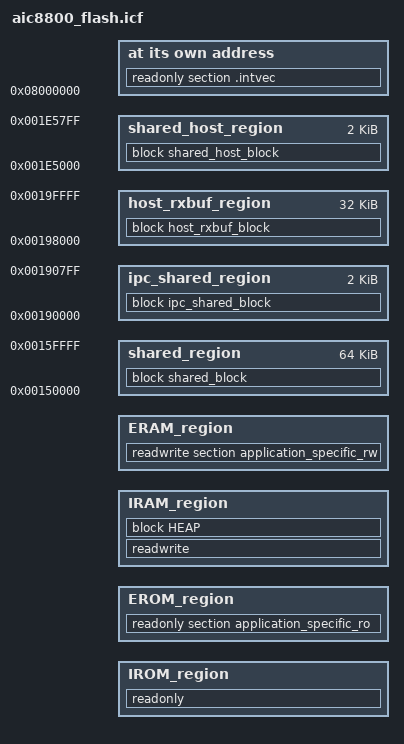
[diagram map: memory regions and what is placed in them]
/*###ICF### Section handled by ICF editor, don't touch! ****/
/*-Editor annotation file-*/
/* IcfEditorFile="$TOOLKIT_DIR$\config\ide\IcfEditor\cortex_v1_4.xml" */
/*-Specials-*/
define symbol __ICFEDIT_intvec_start__ = 0x08000000;
/*-Memory Regions-*/
define symbol __ICFEDIT_region_IROM1_start__ = 0x08000000;
define symbol __ICFEDIT_region_IROM1_end__   = 0x081FBFFF;
define symbol __ICFEDIT_region_IROM2_start__ = 0x0;
define symbol __ICFEDIT_region_IROM2_end__   = 0x0;
define symbol __ICFEDIT_region_EROM1_start__ = 0x0;
define symbol __ICFEDIT_region_EROM1_end__   = 0x0;
define symbol __ICFEDIT_region_EROM2_start__ = 0x0;
define symbol __ICFEDIT_region_EROM2_end__   = 0x0;
define symbol __ICFEDIT_region_EROM3_start__ = 0x0;
define symbol __ICFEDIT_region_EROM3_end__   = 0x0;
define symbol __ICFEDIT_region_IRAM1_start__ = 0x001A0000;
define symbol __ICFEDIT_region_IRAM1_end__   = 0x001C7FFF;
define symbol __ICFEDIT_region_IRAM2_start__ = 0x0;
define symbol __ICFEDIT_region_IRAM2_end__   = 0x0;
define symbol __ICFEDIT_region_ERAM1_start__ = 0x0;
define symbol __ICFEDIT_region_ERAM1_end__   = 0x0;
define symbol __ICFEDIT_region_ERAM2_start__ = 0x0;
define symbol __ICFEDIT_region_ERAM2_end__   = 0x0;
define symbol __ICFEDIT_region_ERAM3_start__ = 0x0;
define symbol __ICFEDIT_region_ERAM3_end__   = 0x0;
/*-Sizes-*/
define symbol __ICFEDIT_size_cstack__     = 0x1000;
define symbol __ICFEDIT_size_proc_stack__ = 0x0;
define symbol __ICFEDIT_size_heap__       = 0x0;
/**** End of ICF editor section. ###ICF###*/

define memory mem with size = 4G;
define symbol use_IROM1 = (__ICFEDIT_region_IROM1_start__ != 0x0 || __ICFEDIT_region_IROM1_end__ != 0x0);
define symbol use_IROM2 = (__ICFEDIT_region_IROM2_start__ != 0x0 || __ICFEDIT_region_IROM2_end__ != 0x0);
define symbol use_EROM1 = (__ICFEDIT_region_EROM1_start__ != 0x0 || __ICFEDIT_region_EROM1_end__ != 0x0);
define symbol use_EROM2 = (__ICFEDIT_region_EROM2_start__ != 0x0 || __ICFEDIT_region_EROM2_end__ != 0x0);
define symbol use_EROM3 = (__ICFEDIT_region_EROM3_start__ != 0x0 || __ICFEDIT_region_EROM3_end__ != 0x0);
define symbol use_IRAM1 = (__ICFEDIT_region_IRAM1_start__ != 0x0 || __ICFEDIT_region_IRAM1_end__ != 0x0);
define symbol use_IRAM2 = (__ICFEDIT_region_IRAM2_start__ != 0x0 || __ICFEDIT_region_IRAM2_end__ != 0x0);
define symbol use_ERAM1 = (__ICFEDIT_region_ERAM1_start__ != 0x0 || __ICFEDIT_region_ERAM1_end__ != 0x0);
define symbol use_ERAM2 = (__ICFEDIT_region_ERAM2_start__ != 0x0 || __ICFEDIT_region_ERAM2_end__ != 0x0);
define symbol use_ERAM3 = (__ICFEDIT_region_ERAM3_start__ != 0x0 || __ICFEDIT_region_ERAM3_end__ != 0x0);

if (use_IROM1)
{
  define region IROM1_region = mem:[from __ICFEDIT_region_IROM1_start__ to __ICFEDIT_region_IROM1_end__];
}
else
{
  define region IROM1_region = [];
}

if (use_IROM2)
{
  define region IROM2_region = mem:[from __ICFEDIT_region_IROM2_start__ to __ICFEDIT_region_IROM2_end__];
}
else
{
  define region IROM2_region = [];
}
define region IROM_region = IROM1_region | IROM2_region;

if (use_EROM1)
{
  define region EROM1_region = mem:[from __ICFEDIT_region_EROM1_start__ to __ICFEDIT_region_EROM1_end__];
}
else
{
  define region EROM1_region = [];
}
if (use_EROM2)
{
  define region EROM2_region = mem:[from __ICFEDIT_region_EROM2_start__ to __ICFEDIT_region_EROM2_end__];
}
else
{
  define region EROM2_region = [];
}
if (use_EROM3)
{
  define region EROM3_region = mem:[from __ICFEDIT_region_EROM3_start__ to __ICFEDIT_region_EROM3_end__];
}
else
{
  define region EROM3_region = [];
}
define region EROM_region = EROM1_region | EROM2_region | EROM3_region;

if (use_IRAM1)
{
  define region IRAM1_region = mem:[from __ICFEDIT_region_IRAM1_start__ to __ICFEDIT_region_IRAM1_end__];
}
else
{
  define region IRAM1_region = [];
}
if (use_IRAM2)
{
  define region IRAM2_region = mem:[from __ICFEDIT_region_IRAM2_start__ to __ICFEDIT_region_IRAM2_end__];
}
else
{
  define region IRAM2_region = [];
}
define region IRAM_region = IRAM1_region | IRAM2_region;

if (use_ERAM1)
{
  define region ERAM1_region = mem:[from __ICFEDIT_region_ERAM1_start__ to __ICFEDIT_region_ERAM1_end__];
}
else
{
  define region ERAM1_region = [];
}
if (use_ERAM2)
{
  define region ERAM2_region = mem:[from __ICFEDIT_region_ERAM2_start__ to __ICFEDIT_region_ERAM2_end__];
}
else
{
  define region ERAM2_region = [];
}
if (use_ERAM3)
{
  define region ERAM3_region = mem:[from __ICFEDIT_region_ERAM3_start__ to __ICFEDIT_region_ERAM3_end__];
}
else
{
  define region ERAM3_region = [];
}
define region ERAM_region = ERAM1_region | ERAM2_region | ERAM3_region;

do not initialize  { section .noinit };
initialize by copy { readwrite };
if (isdefinedsymbol(__USE_DLIB_PERTHREAD))
{
  // Required in a multi-threaded application
  initialize by copy with packing = none { section __DLIB_PERTHREAD };
}

place at address mem:__ICFEDIT_intvec_start__ { readonly section .intvec };

if (!isempty(IROM_region))
{
  place in IROM_region  { readonly };
}

if (!isempty(EROM_region))
{
  place in EROM_region  { readonly section application_specific_ro };
}

if (!isempty(IRAM_region))
{
  define block CSTACK     with alignment = 8, size = __ICFEDIT_size_cstack__     { };
  define block PROC_STACK with alignment = 8, size = __ICFEDIT_size_proc_stack__ { };
  define block HEAP       with alignment = 8, size = __ICFEDIT_size_heap__       { };
  place in IRAM_region  { readwrite, block HEAP };
}

if (!isempty(ERAM_region))
{
  place in ERAM_region  { readwrite section application_specific_rw };
}

/* 320KB from 0x00100000 is used as gram */
/* 64KB from 0x00150000 is used as sharedmen and stacks */
define symbol __shared_memory_start__        = 0x00150000;
define symbol __shared_memory_end__          = 0x0015FFFF;
define region shared_region = mem:[from __shared_memory_start__ to __shared_memory_end__];
define block shared_block { readwrite section SHAREDRAM, block CSTACK, block PROC_STACK };
place in shared_region { block shared_block };

/* Sections for Wifi */
define symbol __ipc_shared_memory_start__    = 0x00190000;
define symbol __ipc_shared_memory_end__      = 0x001907FF;
define region ipc_shared_region = mem:[from __ipc_shared_memory_start__ to __ipc_shared_memory_end__];
define block ipc_shared_block { readwrite section SHAREDRAMIPC };
place in ipc_shared_region { block ipc_shared_block };

define symbol __host_rxbuf_memory_start__    = 0x00198000;
define symbol __host_rxbuf_memory_end__      = 0x0019FFFF;
define region host_rxbuf_region = mem:[from __host_rxbuf_memory_start__ to __host_rxbuf_memory_end__];
define block host_rxbuf_block { readwrite section HOST_RXBUF };
place in host_rxbuf_region { block host_rxbuf_block };

/* Sections for BT */
define symbol __shared_host_start__         = 0x001E5000;
define symbol __shared_host_end__           = 0x001E57FF;
define region shared_host_region = mem:[from __shared_host_start__ to __shared_host_end__];
define block shared_host_block { readwrite section SHAREDMEM_HOST_* };
place in shared_host_region { block shared_host_block };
